# ZB32L030 register map
Vendor: ZBit.; Series: ZB32L03X; File version: 1.0
CPU: CM0+ r1p0, little endian, no MPU, no FPU, VTOR, 2 interrupt priority bits
Registers are 32-bit, read-write, reset 0x0 unless marked. A register's access mark holds for its fields unless they carry their own. Offsets are from the block's base; [hi:lo] are bit positions; {n}, {i} and the like mark numbered series; 'fields as' and 'values as' point back to an identical list.

## CRC
Base 0x40020800
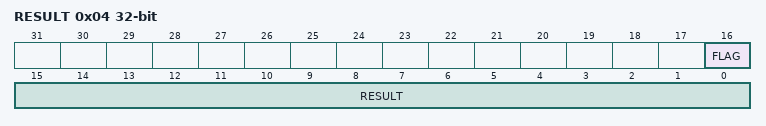
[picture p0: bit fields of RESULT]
0x04 RESULT
  [16] FLAG ro — flag of checksum
  [15:0] RESULT — CRC value
0x80 DATA0 — CRC Data Register (0x80 ~ 0xFF)
  [31:0] CRC_DATA — Input Data

## FLASH — Flash Controller
Base 0x40020400
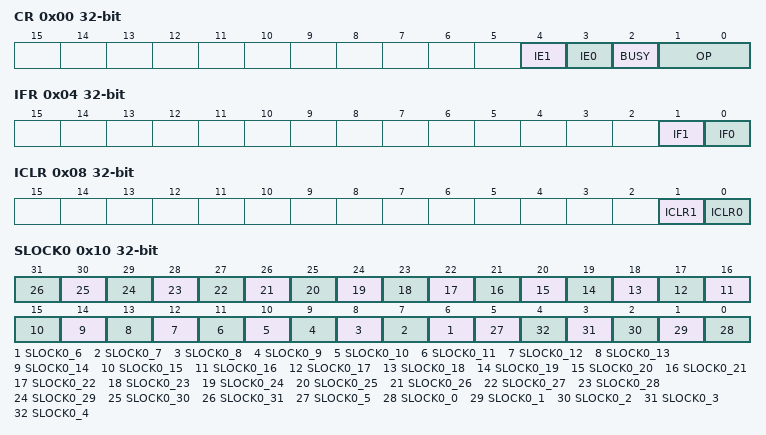
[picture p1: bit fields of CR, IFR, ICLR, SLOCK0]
0x00 CR — Control Register
  [4] IE1 — Enable interrupt of P/E $pc
  [3] IE0 — Enable interrupt of P/E protect block
  [2] BUSY ro — BUSY FLAG
  [1:0] OP — Flash Operation Mode
    0=READ (Flash read); 1=PROG (Flash program); 2=ERASE_SECTOR (Flash sector erase); 3=ERASE_CHIP (Flash chip erase)
0x04 IFR — Interrupt flag Register
  [1] IF1 ro — Interrupt flag of P/E protect block
  [0] IF0 ro — Interrupt flag of P/E $pc
0x08 ICLR — Interrupt Flag Clear Register
  [1] ICLR1 wo — Clear IRQ flag of P/E protect block
  [0] ICLR0 wo — Clear IRQ flag of P/E $pc
0x0C BYPASS — 0X5A5A-0XA5A5 sequence Register
  [15:0] BYPASSSEQ wo
0x10 SLOCK0 — Sector Write Protect Register0
  [n] SLOCK0_{n} (n=6..31) — Sector {2n}~{2n+1}
  [5] SLOCK0_5 — Sector 11~10
  [n] SLOCK0_{n} (n=0..4) — Sector {2n}~{2n+1}
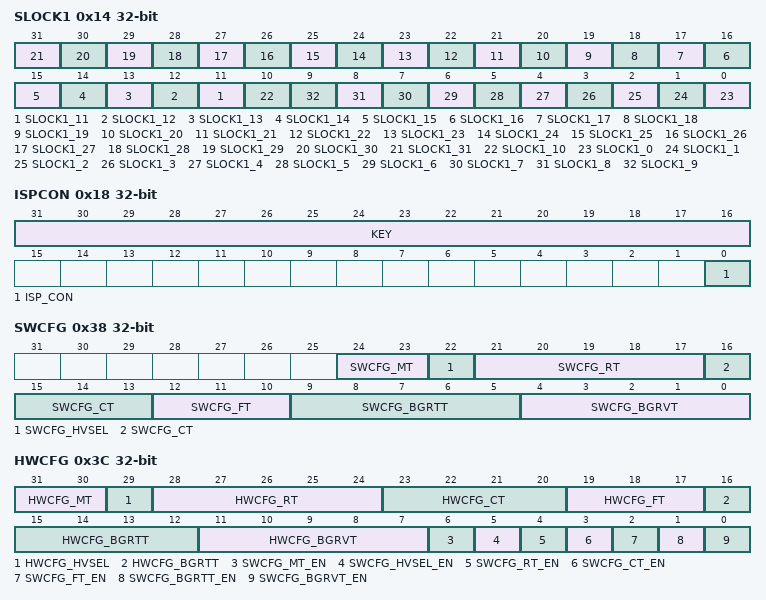
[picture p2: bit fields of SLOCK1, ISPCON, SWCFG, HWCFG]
0x14 SLOCK1 — Sector Write Protect Register1
  [n] SLOCK1_{n} (n=11..31) — Sector {2n+64}~{2n+65}
  [10] SLOCK1_10 — Sector 84~55
  [n] SLOCK1_{n} (n=0..9) — Sector {2n+64}~{2n+65}
0x18 ISPCON — Flash ISP Control register
  [31:16] KEY wo — auth key 0x5A69
  [0] ISP_CON — ISP Function Config (Unlock when KEY=0x5A69)
0x1C IAPCON — Flash IAP Control register
  [0] IAP_CON
0x20 IAP_SIZE — Flash IAP Size register
  [1:0] IAP_SIZE
0x24 ISP_AUX_FLAG
  [0] ISP_AUX_FLAG
0x38 SWCFG — Flash configuration
  [24:23] SWCFG_MT — MT tirmming value
  [22] SWCFG_HVSEL — HVSEL tirmming value
  [21:17] SWCFG_RT — RT tirmming value
  [16:13] SWCFG_CT — CT tirmming value
  [12:10] SWCFG_FT — FT tirmming value
  [9:5] SWCFG_BGRTT — BGRTT tirmming value
  [4:0] SWCFG_BGRVT — BGRVT tirmming value
0x3C HWCFG — Flash configuration
  [31:30] HWCFG_MT ro — MT tirmming value
  [29] HWCFG_HVSEL ro — HVSEL tirmming value
  [28:24] HWCFG_RT ro — RT tirmming value
  [23:20] HWCFG_CT ro — CT tirmming value
  [19:17] HWCFG_FT ro — FT tirmming value
  [16:12] HWCFG_BGRTT ro — BGRTT tirmming value
  [11:7] HWCFG_BGRVT ro — BGRVT tirmming value
  [6] SWCFG_MT_EN — Enable SW MT configurate
  [5] SWCFG_HVSEL_EN — Enable SW HVSEL configurate
  [4] SWCFG_RT_EN — Enable SW RT configurate
  [3] SWCFG_CT_EN — Enable SW CT configurate
  [2] SWCFG_FT_EN — Enable SW FT configurate
  [1] SWCFG_BGRTT_EN — Enable SW BGRTT configurate
  [0] SWCFG_BGRVT_EN — Enable SW BGRVT configurate

## GPIO — GPIO register list
Base 0x40021000
Same registers: GPIOA 0x40021000, GPIOB 0x40021400, GPIOC 0x40021800, GPIOD 0x40021C00
0x00 DIRCR — Input/Output direction Register
  [15:0] PxDIR
    1=Pin 0; 2=Pin 1; 4=Pin 2; 8=Pin 3; 16=Pin 4; 32=Pin 5; 64=Pin 6; 128=Pin 7; 0x100=Pin 8; 0x200=Pin 9; 0x400=Pin 10; 0x800=Pin 11; 0x1000=Pin 12; 0x2000=Pin 13; 0x4000=Pin 14; 0x8000=Pin 15
0x04 OTYPER — Output Type register
  [15:0] PxOTYP — Px Output Type
    values as DIRCR.PxDIR
0x08 ODR — Output Data Register
  [15:0] PxOD — Px Output Value Config
    values as DIRCR.PxDIR
0x0C IDR — Input Data Register
  [15:0] PxID — Px Input Value
    values as DIRCR.PxDIR
0x10 INTEN — Inerrupt Enable Register
  [15:0] PxIEN — Px Interrupt Enable
    values as DIRCR.PxDIR
0x14 RAWINTSR ro — Interrupt Raw Status register
  [15:0] PxRIS
    values as DIRCR.PxDIR
0x18 MSKINTSR ro — Interrupt Status Register
  [15:0] PxMIS
    values as DIRCR.PxDIR
0x1C INTCLR wo — Interrupt Clear Register
  [15:0] PxICLR
    values as DIRCR.PxDIR
0x20 INTTYPCR — Interrupt Style Register
  [15:0] PxITYPE — Px Interrupt type
    values as DIRCR.PxDIR
0x24 INTPOLCR — Interrupt Sytle Value Register
  [15:0] PxIVAL — Px Interrupt Value
    values as DIRCR.PxDIR
0x28 INTANY — Edge Trigger Interrupt Register
  [15:0] PxIANY
    values as DIRCR.PxDIR
0x2C ODSET wo — Output Setting Register
  [15:0] PxODSET — Px Output Setting bit
    values as DIRCR.PxDIR
0x30 ODCLR wo — Output Clear Register
  [15:0] PxODCLR
    values as DIRCR.PxDIR
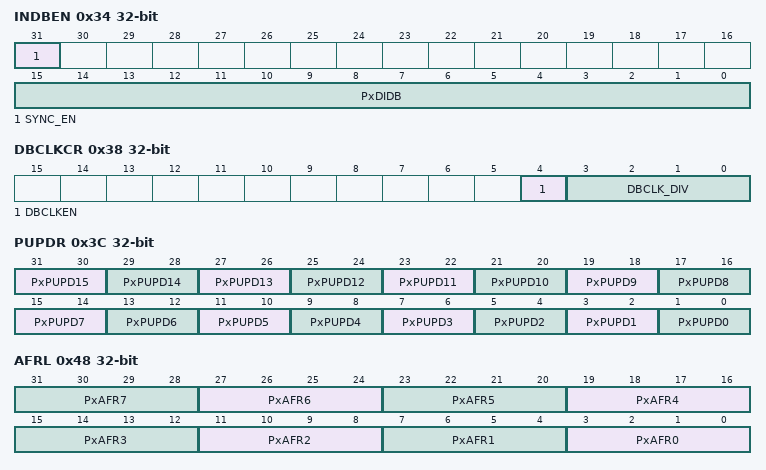
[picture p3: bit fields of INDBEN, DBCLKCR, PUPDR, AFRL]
0x34 INDBEN — Input Debounce and synchronous Enable Register
  [31] SYNC_EN — enable
  [15:0] PxDIDB
    values as DIRCR.PxDIR
0x38 DBCLKCR — Input Debounce clock Config register
  [4] DBCLKEN — DB clock enable
  [3:0] DBCLK_DIV — Debounce CLK
    0=Sample clock HCLK divide 1; 1=Sample clock HCLK divide 2; 2=Sample clock HCLK divide 4; 3=Sample clock HCLK divide 8; 4=Sample clock HCLK divide 16; 5=Sample clock HCLK divide 32; 6=Sample clock HCLK divide 64; 7=Sample clock HCLK divide 128; 8=Sample clock HCLK divide 256; 9=Sample clock HCLK divide 512; 10=Sample clock HCLK divide 1024; 11=Sample clock HCLK divide 2048; 12=Sample clock HCLK divide 4096; 13=Sample clock HCLK divide 8192; 14=Sample clock HCLK divide 16384; 15=Sample clock HCLK divide 32768
0x3C PUPDR — PullUp and PullDown Register
  [2n+1:2n] PxPUPD{n} (n=1..15) — Px PullUP PullDown
  [1:0] PxPUPD0 — Px PullUP PullDown
    0=NO (No pull-up, pull-down); 1=PU (Pull-up); 2=PD (pull-down)
0x40 SLEWCR — Voltage Convertion Speed Control
  [15:0] PxSR
    values as DIRCR.PxDIR
0x44 DRVCR — Driver Strength Config
  [15:0] PxDRV
    values as DIRCR.PxDIR
0x48 AFRL — Alternate Function Register (0 ~7)
  [4n+3:4n] PxAFR{n} (n=0..7) — Px AFR
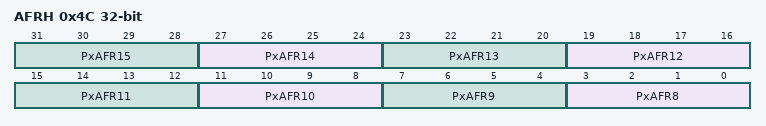
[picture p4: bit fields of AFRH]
0x4C AFRH — Alternate Function Register (8 ~ 15)
  [4n-29:4n-32] PxAFR{n} (n=8..15) — Px AFR
